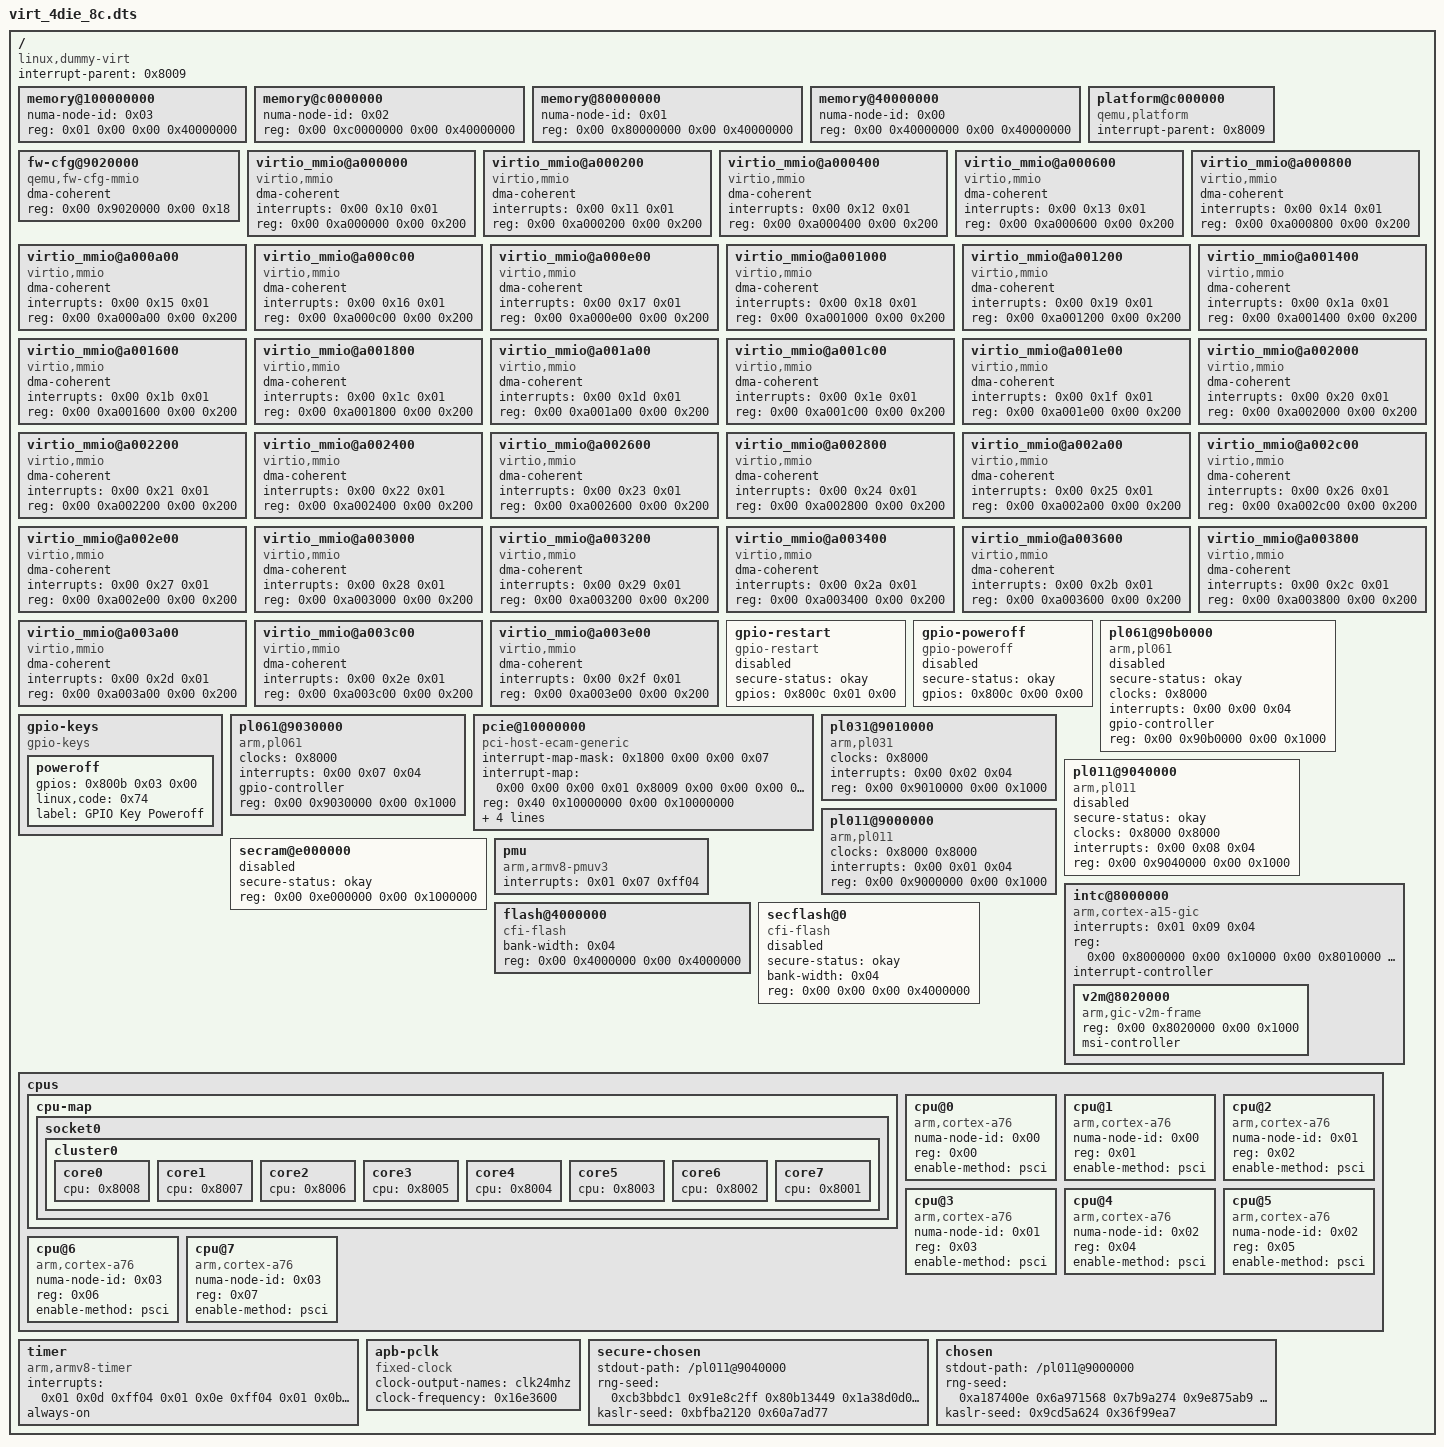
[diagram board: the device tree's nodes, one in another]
/dts-v1/;

/ {
	interrupt-parent = <0x8009>;
	#size-cells = <0x02>;
	#address-cells = <0x02>;
	compatible = "linux,dummy-virt";

	memory@100000000 {
		numa-node-id = <0x03>;
		reg = <0x01 0x00 0x00 0x40000000>;
		device_type = "memory";
	};

	memory@c0000000 {
		numa-node-id = <0x02>;
		reg = <0x00 0xc0000000 0x00 0x40000000>;
		device_type = "memory";
	};

	memory@80000000 {
		numa-node-id = <0x01>;
		reg = <0x00 0x80000000 0x00 0x40000000>;
		device_type = "memory";
	};

	memory@40000000 {
		numa-node-id = <0x00>;
		reg = <0x00 0x40000000 0x00 0x40000000>;
		device_type = "memory";
	};

	platform@c000000 {
		interrupt-parent = <0x8009>;
		ranges = <0x00 0x00 0xc000000 0x2000000>;
		#address-cells = <0x01>;
		#size-cells = <0x01>;
		compatible = "qemu,platform\0simple-bus";
	};

	fw-cfg@9020000 {
		dma-coherent;
		reg = <0x00 0x9020000 0x00 0x18>;
		compatible = "qemu,fw-cfg-mmio";
	};

	virtio_mmio@a000000 {
		dma-coherent;
		interrupts = <0x00 0x10 0x01>;
		reg = <0x00 0xa000000 0x00 0x200>;
		compatible = "virtio,mmio";
	};

	virtio_mmio@a000200 {
		dma-coherent;
		interrupts = <0x00 0x11 0x01>;
		reg = <0x00 0xa000200 0x00 0x200>;
		compatible = "virtio,mmio";
	};

	virtio_mmio@a000400 {
		dma-coherent;
		interrupts = <0x00 0x12 0x01>;
		reg = <0x00 0xa000400 0x00 0x200>;
		compatible = "virtio,mmio";
	};

	virtio_mmio@a000600 {
		dma-coherent;
		interrupts = <0x00 0x13 0x01>;
		reg = <0x00 0xa000600 0x00 0x200>;
		compatible = "virtio,mmio";
	};

	virtio_mmio@a000800 {
		dma-coherent;
		interrupts = <0x00 0x14 0x01>;
		reg = <0x00 0xa000800 0x00 0x200>;
		compatible = "virtio,mmio";
	};

	virtio_mmio@a000a00 {
		dma-coherent;
		interrupts = <0x00 0x15 0x01>;
		reg = <0x00 0xa000a00 0x00 0x200>;
		compatible = "virtio,mmio";
	};

	virtio_mmio@a000c00 {
		dma-coherent;
		interrupts = <0x00 0x16 0x01>;
		reg = <0x00 0xa000c00 0x00 0x200>;
		compatible = "virtio,mmio";
	};

	virtio_mmio@a000e00 {
		dma-coherent;
		interrupts = <0x00 0x17 0x01>;
		reg = <0x00 0xa000e00 0x00 0x200>;
		compatible = "virtio,mmio";
	};

	virtio_mmio@a001000 {
		dma-coherent;
		interrupts = <0x00 0x18 0x01>;
		reg = <0x00 0xa001000 0x00 0x200>;
		compatible = "virtio,mmio";
	};

	virtio_mmio@a001200 {
		dma-coherent;
		interrupts = <0x00 0x19 0x01>;
		reg = <0x00 0xa001200 0x00 0x200>;
		compatible = "virtio,mmio";
	};

	virtio_mmio@a001400 {
		dma-coherent;
		interrupts = <0x00 0x1a 0x01>;
		reg = <0x00 0xa001400 0x00 0x200>;
		compatible = "virtio,mmio";
	};

	virtio_mmio@a001600 {
		dma-coherent;
		interrupts = <0x00 0x1b 0x01>;
		reg = <0x00 0xa001600 0x00 0x200>;
		compatible = "virtio,mmio";
	};

	virtio_mmio@a001800 {
		dma-coherent;
		interrupts = <0x00 0x1c 0x01>;
		reg = <0x00 0xa001800 0x00 0x200>;
		compatible = "virtio,mmio";
	};

	virtio_mmio@a001a00 {
		dma-coherent;
		interrupts = <0x00 0x1d 0x01>;
		reg = <0x00 0xa001a00 0x00 0x200>;
		compatible = "virtio,mmio";
	};

	virtio_mmio@a001c00 {
		dma-coherent;
		interrupts = <0x00 0x1e 0x01>;
		reg = <0x00 0xa001c00 0x00 0x200>;
		compatible = "virtio,mmio";
	};

	virtio_mmio@a001e00 {
		dma-coherent;
		interrupts = <0x00 0x1f 0x01>;
		reg = <0x00 0xa001e00 0x00 0x200>;
		compatible = "virtio,mmio";
	};

	virtio_mmio@a002000 {
		dma-coherent;
		interrupts = <0x00 0x20 0x01>;
		reg = <0x00 0xa002000 0x00 0x200>;
		compatible = "virtio,mmio";
	};

	virtio_mmio@a002200 {
		dma-coherent;
		interrupts = <0x00 0x21 0x01>;
		reg = <0x00 0xa002200 0x00 0x200>;
		compatible = "virtio,mmio";
	};

	virtio_mmio@a002400 {
		dma-coherent;
		interrupts = <0x00 0x22 0x01>;
		reg = <0x00 0xa002400 0x00 0x200>;
		compatible = "virtio,mmio";
	};

	virtio_mmio@a002600 {
		dma-coherent;
		interrupts = <0x00 0x23 0x01>;
		reg = <0x00 0xa002600 0x00 0x200>;
		compatible = "virtio,mmio";
	};

	virtio_mmio@a002800 {
		dma-coherent;
		interrupts = <0x00 0x24 0x01>;
		reg = <0x00 0xa002800 0x00 0x200>;
		compatible = "virtio,mmio";
	};

	virtio_mmio@a002a00 {
		dma-coherent;
		interrupts = <0x00 0x25 0x01>;
		reg = <0x00 0xa002a00 0x00 0x200>;
		compatible = "virtio,mmio";
	};

	virtio_mmio@a002c00 {
		dma-coherent;
		interrupts = <0x00 0x26 0x01>;
		reg = <0x00 0xa002c00 0x00 0x200>;
		compatible = "virtio,mmio";
	};

	virtio_mmio@a002e00 {
		dma-coherent;
		interrupts = <0x00 0x27 0x01>;
		reg = <0x00 0xa002e00 0x00 0x200>;
		compatible = "virtio,mmio";
	};

	virtio_mmio@a003000 {
		dma-coherent;
		interrupts = <0x00 0x28 0x01>;
		reg = <0x00 0xa003000 0x00 0x200>;
		compatible = "virtio,mmio";
	};

	virtio_mmio@a003200 {
		dma-coherent;
		interrupts = <0x00 0x29 0x01>;
		reg = <0x00 0xa003200 0x00 0x200>;
		compatible = "virtio,mmio";
	};

	virtio_mmio@a003400 {
		dma-coherent;
		interrupts = <0x00 0x2a 0x01>;
		reg = <0x00 0xa003400 0x00 0x200>;
		compatible = "virtio,mmio";
	};

	virtio_mmio@a003600 {
		dma-coherent;
		interrupts = <0x00 0x2b 0x01>;
		reg = <0x00 0xa003600 0x00 0x200>;
		compatible = "virtio,mmio";
	};

	virtio_mmio@a003800 {
		dma-coherent;
		interrupts = <0x00 0x2c 0x01>;
		reg = <0x00 0xa003800 0x00 0x200>;
		compatible = "virtio,mmio";
	};

	virtio_mmio@a003a00 {
		dma-coherent;
		interrupts = <0x00 0x2d 0x01>;
		reg = <0x00 0xa003a00 0x00 0x200>;
		compatible = "virtio,mmio";
	};

	virtio_mmio@a003c00 {
		dma-coherent;
		interrupts = <0x00 0x2e 0x01>;
		reg = <0x00 0xa003c00 0x00 0x200>;
		compatible = "virtio,mmio";
	};

	virtio_mmio@a003e00 {
		dma-coherent;
		interrupts = <0x00 0x2f 0x01>;
		reg = <0x00 0xa003e00 0x00 0x200>;
		compatible = "virtio,mmio";
	};

	gpio-restart {
		secure-status = "okay";
		status = "disabled";
		gpios = <0x800c 0x01 0x00>;
		compatible = "gpio-restart";
	};

	gpio-poweroff {
		secure-status = "okay";
		status = "disabled";
		gpios = <0x800c 0x00 0x00>;
		compatible = "gpio-poweroff";
	};

	pl061@90b0000 {
		secure-status = "okay";
		status = "disabled";
		phandle = <0x800c>;
		clock-names = "apb_pclk";
		clocks = <0x8000>;
		interrupts = <0x00 0x00 0x04>;
		gpio-controller;
		#gpio-cells = <0x02>;
		compatible = "arm,pl061\0arm,primecell";
		reg = <0x00 0x90b0000 0x00 0x1000>;
	};

	gpio-keys {
		compatible = "gpio-keys";

		poweroff {
			gpios = <0x800b 0x03 0x00>;
			linux,code = <0x74>;
			label = "GPIO Key Poweroff";
		};
	};

	pl061@9030000 {
		phandle = <0x800b>;
		clock-names = "apb_pclk";
		clocks = <0x8000>;
		interrupts = <0x00 0x07 0x04>;
		gpio-controller;
		#gpio-cells = <0x02>;
		compatible = "arm,pl061\0arm,primecell";
		reg = <0x00 0x9030000 0x00 0x1000>;
	};

	pcie@10000000 {
		interrupt-map-mask = <0x1800 0x00 0x00 0x07>;
		interrupt-map = <0x00 0x00 0x00 0x01 0x8009 0x00 0x00 0x00 0x03 0x04 0x00 0x00 0x00 0x02 0x8009 0x00 0x00 0x00 0x04 0x04 0x00 0x00 0x00 0x03 0x8009 0x00 0x00 0x00 0x05 0x04 0x00 0x00 0x00 0x04 0x8009 0x00 0x00 0x00 0x06 0x04 0x800 0x00 0x00 0x01 0x8009 0x00 0x00 0x00 0x04 0x04 0x800 0x00 0x00 0x02 0x8009 0x00 0x00 0x00 0x05 0x04 0x800 0x00 0x00 0x03 0x8009 0x00 0x00 0x00 0x06 0x04 0x800 0x00 0x00 0x04 0x8009 0x00 0x00 0x00 0x03 0x04 0x1000 0x00 0x00 0x01 0x8009 0x00 0x00 0x00 0x05 0x04 0x1000 0x00 0x00 0x02 0x8009 0x00 0x00 0x00 0x06 0x04 0x1000 0x00 0x00 0x03 0x8009 0x00 0x00 0x00 0x03 0x04 0x1000 0x00 0x00 0x04 0x8009 0x00 0x00 0x00 0x04 0x04 0x1800 0x00 0x00 0x01 0x8009 0x00 0x00 0x00 0x06 0x04 0x1800 0x00 0x00 0x02 0x8009 0x00 0x00 0x00 0x03 0x04 0x1800 0x00 0x00 0x03 0x8009 0x00 0x00 0x00 0x04 0x04 0x1800 0x00 0x00 0x04 0x8009 0x00 0x00 0x00 0x05 0x04>;
		#interrupt-cells = <0x01>;
		ranges = <0x1000000 0x00 0x00 0x00 0x3eff0000 0x00 0x10000 0x2000000 0x00 0x10000000 0x00 0x10000000 0x00 0x2eff0000 0x3000000 0x80 0x00 0x80 0x00 0x80 0x00>;
		reg = <0x40 0x10000000 0x00 0x10000000>;
		msi-parent = <0x800a>;
		dma-coherent;
		bus-range = <0x00 0xff>;
		linux,pci-domain = <0x00>;
		#size-cells = <0x02>;
		#address-cells = <0x03>;
		device_type = "pci";
		compatible = "pci-host-ecam-generic";
	};

	pl031@9010000 {
		clock-names = "apb_pclk";
		clocks = <0x8000>;
		interrupts = <0x00 0x02 0x04>;
		reg = <0x00 0x9010000 0x00 0x1000>;
		compatible = "arm,pl031\0arm,primecell";
	};

	pl011@9040000 {
		secure-status = "okay";
		status = "disabled";
		clock-names = "uartclk\0apb_pclk";
		clocks = <0x8000 0x8000>;
		interrupts = <0x00 0x08 0x04>;
		reg = <0x00 0x9040000 0x00 0x1000>;
		compatible = "arm,pl011\0arm,primecell";
	};

	secram@e000000 {
		secure-status = "okay";
		status = "disabled";
		reg = <0x00 0xe000000 0x00 0x1000000>;
		device_type = "memory";
	};

	pl011@9000000 {
		clock-names = "uartclk\0apb_pclk";
		clocks = <0x8000 0x8000>;
		interrupts = <0x00 0x01 0x04>;
		reg = <0x00 0x9000000 0x00 0x1000>;
		compatible = "arm,pl011\0arm,primecell";
	};

	pmu {
		interrupts = <0x01 0x07 0xff04>;
		compatible = "arm,armv8-pmuv3";
	};

	intc@8000000 {
		phandle = <0x8009>;
		interrupts = <0x01 0x09 0x04>;
		reg = <0x00 0x8000000 0x00 0x10000 0x00 0x8010000 0x00 0x10000 0x00 0x8030000 0x00 0x10000 0x00 0x8040000 0x00 0x10000>;
		compatible = "arm,cortex-a15-gic";
		ranges;
		#size-cells = <0x02>;
		#address-cells = <0x02>;
		interrupt-controller;
		#interrupt-cells = <0x03>;

		v2m@8020000 {
			phandle = <0x800a>;
			reg = <0x00 0x8020000 0x00 0x1000>;
			msi-controller;
			compatible = "arm,gic-v2m-frame";
		};
	};

	flash@4000000 {
		bank-width = <0x04>;
		reg = <0x00 0x4000000 0x00 0x4000000>;
		compatible = "cfi-flash";
	};

	secflash@0 {
		secure-status = "okay";
		status = "disabled";
		bank-width = <0x04>;
		reg = <0x00 0x00 0x00 0x4000000>;
		compatible = "cfi-flash";
	};

	cpus {
		#size-cells = <0x00>;
		#address-cells = <0x01>;

		cpu-map {

			socket0 {

				cluster0 {

					core0 {
						cpu = <0x8008>;
					};

					core1 {
						cpu = <0x8007>;
					};

					core2 {
						cpu = <0x8006>;
					};

					core3 {
						cpu = <0x8005>;
					};

					core4 {
						cpu = <0x8004>;
					};

					core5 {
						cpu = <0x8003>;
					};

					core6 {
						cpu = <0x8002>;
					};

					core7 {
						cpu = <0x8001>;
					};
				};
			};
		};

		cpu@0 {
			phandle = <0x8008>;
			numa-node-id = <0x00>;
			reg = <0x00>;
			enable-method = "psci";
			compatible = "arm,cortex-a76";
			device_type = "cpu";
		};

		cpu@1 {
			phandle = <0x8007>;
			numa-node-id = <0x00>;
			reg = <0x01>;
			enable-method = "psci";
			compatible = "arm,cortex-a76";
			device_type = "cpu";
		};

		cpu@2 {
			phandle = <0x8006>;
			numa-node-id = <0x01>;
			reg = <0x02>;
			enable-method = "psci";
			compatible = "arm,cortex-a76";
			device_type = "cpu";
		};

		cpu@3 {
			phandle = <0x8005>;
			numa-node-id = <0x01>;
			reg = <0x03>;
			enable-method = "psci";
			compatible = "arm,cortex-a76";
			device_type = "cpu";
		};

		cpu@4 {
			phandle = <0x8004>;
			numa-node-id = <0x02>;
			reg = <0x04>;
			enable-method = "psci";
			compatible = "arm,cortex-a76";
			device_type = "cpu";
		};

		cpu@5 {
			phandle = <0x8003>;
			numa-node-id = <0x02>;
			reg = <0x05>;
			enable-method = "psci";
			compatible = "arm,cortex-a76";
			device_type = "cpu";
		};

		cpu@6 {
			phandle = <0x8002>;
			numa-node-id = <0x03>;
			reg = <0x06>;
			enable-method = "psci";
			compatible = "arm,cortex-a76";
			device_type = "cpu";
		};

		cpu@7 {
			phandle = <0x8001>;
			numa-node-id = <0x03>;
			reg = <0x07>;
			enable-method = "psci";
			compatible = "arm,cortex-a76";
			device_type = "cpu";
		};
	};

	timer {
		interrupts = <0x01 0x0d 0xff04 0x01 0x0e 0xff04 0x01 0x0b 0xff04 0x01 0x0a 0xff04>;
		always-on;
		compatible = "arm,armv8-timer\0arm,armv7-timer";
	};

	apb-pclk {
		phandle = <0x8000>;
		clock-output-names = "clk24mhz";
		clock-frequency = <0x16e3600>;
		#clock-cells = <0x00>;
		compatible = "fixed-clock";
	};

	secure-chosen {
		stdout-path = "/pl011@9040000";
		rng-seed = <0xcb3bbdc1 0x91e8c2ff 0x80b13449 0x1a38d0d0 0xb3bf5cc7 0x73d58c55 0xc69a2427 0xc7ffd615>;
		kaslr-seed = <0xbfba2120 0x60a7ad77>;
	};

	chosen {
		stdout-path = "/pl011@9000000";
		rng-seed = <0xa187400e 0x6a971568 0x7b9a274 0x9e875ab9 0x98629cfc 0x6fd4c558 0xe215bad3 0x4f5bd018>;
		kaslr-seed = <0x9cd5a624 0x36f99ea7>;
	};
};
